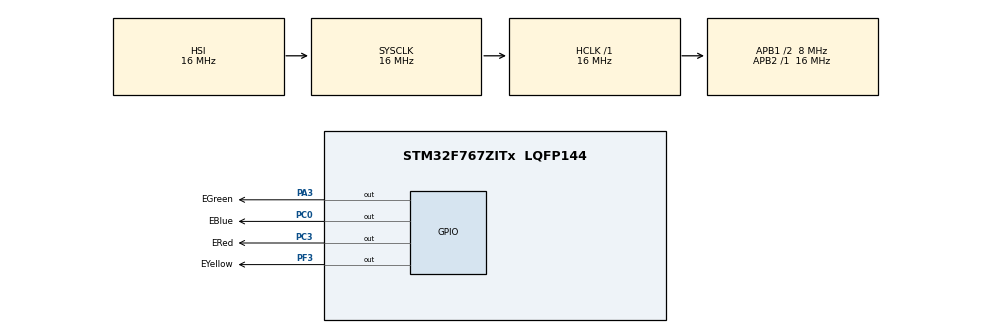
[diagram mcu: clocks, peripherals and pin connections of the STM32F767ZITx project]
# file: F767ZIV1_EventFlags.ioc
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Mcu.Family=STM32F7
RCC.CortexFreq_Value=16000000
FREERTOS.Tasks01=greenProducer,0,128,greenProducerHook,Default,NULL,Dynamic,NULL,NULL;redProducer,0,128,redProducerHook,Default,NULL,Dynamic,NULL,NULL;yellowProducer,0,128,yellowProducerHook,Default,NULL,Dynamic,NULL,NULL;blueConsumer,0,128,blueConsumerHook,Default,NULL,Dynamic,NULL,NULL
RCC.SYSCLKSourceVirtual=RCC_SYSCLKSOURCE_PLLCLK
PC0.GPIO_Label=EBlue
PC0.Signal=GPIO_Output
RCC.APB1CLKDivider=RCC_HCLK_DIV2
ProjectManager.StackSize=0x400
ProjectManager.TargetToolchain=STM32CubeIDE
RCC.HCLKFreq_Value=16000000
RCC.APB2TimFreq_Value=16000000
PC3.Signal=GPIO_Output
RCC.USBFreq_Value=96000000
RCC.LSE_VALUE=32768
RCC.AHBFreq_Value=16000000
RCC.HSE_VALUE=16000000
board=NUCLEO-F767ZI
RCC.VCOOutputFreq_Value=192000000
RCC.PLLMUL=RCC_PLL_MUL9
RCC.APB2Freq_Value=16000000
RCC.PRESCALERUSB=RCC_USBCLKSOURCE_PLL_DIV1_5
VP_SYS_VS_tim1.Mode=TIM1
PF3.Signal=GPIO_Output
VP_FREERTOS_VS_CMSIS_V1.Mode=CMSIS_V1
Mcu.Name=STM32F767ZITx
RCC.48MHZClocksFreq_Value=24000000
RCC.SYSCLKFreq_VALUE=16000000
Mcu.Package=LQFP144
NVIC.TimeBase=TIM1_UP_TIM10_IRQn
NVIC.TimeBaseIP=TIM1
ProjectManager.HeapSize=0x200
NVIC.TIM1_UP_TIM10_IRQn=true\:0\:0\:false\:false\:true\:false\:false\:true
RCC.HSI_VALUE=16000000
NVIC.PriorityGroup=NVIC_PRIORITYGROUP_4
RCC.APB1TimFreq_Value=16000000
PC3.GPIO_Label=ERed
RCC.APB1Freq_Value=8000000
PF3.GPIO_Label=EYellow
PA3.GPIO_Label=EGreen
PA3.Signal=GPIO_Output

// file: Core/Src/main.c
/* USER CODE BEGIN Header */
/**
  ******************************************************************************
  * @file           : main.c
  * @brief          : Main program body
  ******************************************************************************
  * @attention
  *
  * <h2><center>&copy; Copyright (c) 2021 STMicroelectronics.
  * All rights reserved.</center></h2>
  *
  * This software component is licensed by ST under Ultimate Liberty license
  * SLA0044, the "License"; You may not use this file except in compliance with
  * the License. You may obtain a copy of the License at:
  *                             www.st.com/SLA0044
  *
  ******************************************************************************
  */
/* USER CODE END Header */
#include "main.h"
#include "cmsis_os.h"
#include "stdlib.h"

osThreadId greenProducerHandle;
osThreadId redProducerHandle;
osThreadId yellowProducerHandle;
osThreadId blueConsumerHandle;

void SystemClock_Config(void);
static void MX_GPIO_Init(void);
void greenProducerHook(void const * argument);
void redProducerHook(void const * argument);
void yellowProducerHook(void const * argument);
void blueConsumerHook(void const * argument);
void toggle(GPIO_TypeDef*  GPIOx, uint16_t GPIO_Pin, uint32_t frequency, int duration);

int main(void)
{

  /* MCU Configuration--------------------------------------------------------*/

  /* Reset of all peripherals, Initializes the Flash interface and the Systick. */
  HAL_Init();

  /* Configure the system clock */
  SystemClock_Config();

  /* Initialize all configured peripherals */
  MX_GPIO_Init();

  /* Create the thread(s) */
  /* definition and creation of greenProducer */
  osThreadDef(greenProducer, greenProducerHook, osPriorityNormal, 0, 128);
  greenProducerHandle = osThreadCreate(osThread(greenProducer), NULL);

  /* definition and creation of redProducer */
  osThreadDef(redProducer, redProducerHook, osPriorityNormal, 0, 128);
  redProducerHandle = osThreadCreate(osThread(redProducer), NULL);

  /* definition and creation of yellowProducer */
  osThreadDef(yellowProducer, yellowProducerHook, osPriorityNormal, 0, 128);
  yellowProducerHandle = osThreadCreate(osThread(yellowProducer), NULL);

  /* definition and creation of blueConsumer */
  osThreadDef(blueConsumer, blueConsumerHook, osPriorityNormal, 0, 128);
  blueConsumerHandle = osThreadCreate(osThread(blueConsumer), NULL);

  /* Start scheduler */
  osKernelStart();

  /* We should never get here as control is now taken by the scheduler */
  /* Infinite loop */
  while (1)
  {

  }
}

void SystemClock_Config(void)
{
  RCC_OscInitTypeDef RCC_OscInitStruct = {0};
  RCC_ClkInitTypeDef RCC_ClkInitStruct = {0};

  /** Configure the main internal regulator output voltage
  */
  __HAL_RCC_PWR_CLK_ENABLE();
  __HAL_PWR_VOLTAGESCALING_CONFIG(PWR_REGULATOR_VOLTAGE_SCALE3);
  /** Initializes the RCC Oscillators according to the specified parameters
  * in the RCC_OscInitTypeDef structure.
  */
  RCC_OscInitStruct.OscillatorType = RCC_OSCILLATORTYPE_HSI;
  RCC_OscInitStruct.HSIState = RCC_HSI_ON;
  RCC_OscInitStruct.HSICalibrationValue = RCC_HSICALIBRATION_DEFAULT;
  RCC_OscInitStruct.PLL.PLLState = RCC_PLL_NONE;
  if (HAL_RCC_OscConfig(&RCC_OscInitStruct) != HAL_OK)
  {
    Error_Handler();
  }
  /** Initializes the CPU, AHB and APB buses clocks
  */
  RCC_ClkInitStruct.ClockType = RCC_CLOCKTYPE_HCLK|RCC_CLOCKTYPE_SYSCLK
                              |RCC_CLOCKTYPE_PCLK1|RCC_CLOCKTYPE_PCLK2;
  RCC_ClkInitStruct.SYSCLKSource = RCC_SYSCLKSOURCE_HSI;
  RCC_ClkInitStruct.AHBCLKDivider = RCC_SYSCLK_DIV1;
  RCC_ClkInitStruct.APB1CLKDivider = RCC_HCLK_DIV2;
  RCC_ClkInitStruct.APB2CLKDivider = RCC_HCLK_DIV1;

  if (HAL_RCC_ClockConfig(&RCC_ClkInitStruct, FLASH_LATENCY_0) != HAL_OK)
  {
    Error_Handler();
  }
}

static void MX_GPIO_Init(void)
{
  GPIO_InitTypeDef GPIO_InitStruct = {0};

  /* GPIO Ports Clock Enable */
  __HAL_RCC_GPIOF_CLK_ENABLE();
  __HAL_RCC_GPIOC_CLK_ENABLE();
  __HAL_RCC_GPIOA_CLK_ENABLE();

  /*Configure GPIO pin Output Level */
  HAL_GPIO_WritePin(EYellow_GPIO_Port, EYellow_Pin, GPIO_PIN_RESET);

  /*Configure GPIO pin Output Level */
  HAL_GPIO_WritePin(GPIOC, EBlue_Pin|ERed_Pin, GPIO_PIN_RESET);

  /*Configure GPIO pin Output Level */
  HAL_GPIO_WritePin(EGreen_GPIO_Port, EGreen_Pin, GPIO_PIN_RESET);

  /*Configure GPIO pin : EYellow_Pin */
  GPIO_InitStruct.Pin = EYellow_Pin;
  GPIO_InitStruct.Mode = GPIO_MODE_OUTPUT_PP;
  GPIO_InitStruct.Pull = GPIO_NOPULL;
  GPIO_InitStruct.Speed = GPIO_SPEED_FREQ_LOW;
  HAL_GPIO_Init(EYellow_GPIO_Port, &GPIO_InitStruct);

  /*Configure GPIO pins : EBlue_Pin ERed_Pin */
  GPIO_InitStruct.Pin = EBlue_Pin|ERed_Pin;
  GPIO_InitStruct.Mode = GPIO_MODE_OUTPUT_PP;
  GPIO_InitStruct.Pull = GPIO_NOPULL;
  GPIO_InitStruct.Speed = GPIO_SPEED_FREQ_LOW;
  HAL_GPIO_Init(GPIOC, &GPIO_InitStruct);

  /*Configure GPIO pin : EGreen_Pin */
  GPIO_InitStruct.Pin = EGreen_Pin;
  GPIO_InitStruct.Mode = GPIO_MODE_OUTPUT_PP;
  GPIO_InitStruct.Pull = GPIO_NOPULL;
  GPIO_InitStruct.Speed = GPIO_SPEED_FREQ_LOW;
  HAL_GPIO_Init(EGreen_GPIO_Port, &GPIO_InitStruct);

}

/* USER CODE BEGIN 4 */
void toggle(GPIO_TypeDef*  GPIOx, uint16_t GPIO_Pin, uint32_t frequency, int duration)
{
	TickType_t start = xTaskGetTickCount();

	do {
		HAL_GPIO_TogglePin(GPIOx, GPIO_Pin);
		HAL_Delay(frequency);
	} while((xTaskGetTickCount() - start) <= duration);
}
/* USER CODE END 4 */

void greenProducerHook(void const * argument)
{	int delay = 0;

	for(;;){
		toggle(EGreen_GPIO_Port, EGreen_Pin, (uint32_t) 100, 2000);
		osSignalSet(blueConsumerHandle, 0x01);
		delay  = rand() % 1000 + 1000;
		HAL_Delay(delay);
	}
}

void redProducerHook(void const * argument)
{	int delay = 0;
	for(;;){
		toggle(ERed_GPIO_Port, ERed_Pin, (uint32_t) 100, 2000);
		osSignalSet(blueConsumerHandle, 0x10);
		delay  = rand() % 1000 + 1000;
		HAL_Delay(delay);
	}
}

void yellowProducerHook(void const * argument)
{	int delay = 0;
	for(;;){
		toggle(EYellow_GPIO_Port, EYellow_Pin, (uint32_t) 100, 2000);
		osSignalSet(blueConsumerHandle, 0x100);
		delay  = rand() % 1000 + 1000;
		HAL_Delay(delay);
	}
}
void blueConsumerHook(void const * argument)
{
	for(;;)
	{
		osSignalWait(0x111, osWaitForever);
		toggle(EBlue_GPIO_Port, EBlue_Pin, (uint32_t) 100, 1000);
	}
}
 /**
  * @brief  Period elapsed callback in non blocking mode
  * @note   This function is called  when TIM1 interrupt took place, inside
  * HAL_TIM_IRQHandler(). It makes a direct call to HAL_IncTick() to increment
  * a global variable "uwTick" used as application time base.
  * @param  htim : TIM handle
  * @retval None
  */
void HAL_TIM_PeriodElapsedCallback(TIM_HandleTypeDef *htim)
{
  if (htim->Instance == TIM1) {
    HAL_IncTick();
  }
}

void Error_Handler(void)
{
  __disable_irq();
  while (1)
  {
  }
}

/************************ (C) COPYRIGHT STMicroelectronics *****END OF FILE****/
